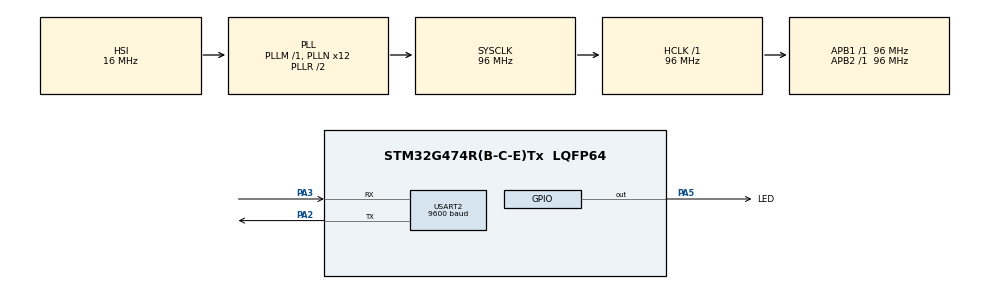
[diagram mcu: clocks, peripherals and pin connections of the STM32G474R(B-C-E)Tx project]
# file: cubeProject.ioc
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Mcu.Family=STM32G4
Mcu.Name=STM32G474R(B-C-E)Tx
Mcu.Package=LQFP64
NVIC.PriorityGroup=NVIC_PRIORITYGROUP_4
PA2.Mode=Asynchronous
PA2.Signal=USART2_TX
PA3.Mode=Asynchronous
PA3.Signal=USART2_RX
PA5.GPIO_Label=LED
PA5.Signal=GPIO_Output
PF0-OSC_IN.Mode=HSE-External-Oscillator
PF0-OSC_IN.Signal=RCC_OSC_IN
PF1-OSC_OUT.Mode=HSE-External-Oscillator
PF1-OSC_OUT.Signal=RCC_OSC_OUT
ProjectManager.HeapSize=0x200
ProjectManager.StackSize=0x400
ProjectManager.TargetToolchain=CMake
RCC.ADC12Freq_Value=96000000
RCC.ADC345Freq_Value=96000000
RCC.AHBFreq_Value=96000000
RCC.APB1Freq_Value=96000000
RCC.APB1TimFreq_Value=96000000
RCC.APB2Freq_Value=96000000
RCC.APB2TimFreq_Value=96000000
RCC.CortexFreq_Value=96000000
RCC.EXTERNAL_CLOCK_VALUE=12288000
RCC.HCLKFreq_Value=96000000
RCC.HSE_VALUE=16000000
RCC.HSI48_VALUE=48000000
RCC.HSI_VALUE=16000000
RCC.LSE_VALUE=32768
RCC.PLLN=12
RCC.PLLQ=RCC_PLLQ_DIV4
RCC.SYSCLKFreq_VALUE=96000000
RCC.SYSCLKSource=RCC_SYSCLKSOURCE_PLLCLK
RCC.USBFreq_Value=48000000
RCC.VCOOutputFreq_Value=192000000
USART2.BaudRate=9600
USART2.VirtualMode-Asynchronous=VM_ASYNC
VP_RNG_VS_RNG.Mode=RNG_Activate
VP_SYS_VS_DBSignals.Mode=DisableDeadBatterySignals
board=custom

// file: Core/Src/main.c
/* USER CODE BEGIN Header */
/**
  ******************************************************************************
  * @file           : main.c
  * @brief          : Main program body
  ******************************************************************************
  * @attention
  *
  * Copyright (c) 2026 STMicroelectronics.
  * All rights reserved.
  *
  * This software is licensed under terms that can be found in the LICENSE file
  * in the root directory of this software component.
  * If no LICENSE file comes with this software, it is provided AS-IS.
  *
  ******************************************************************************
  */
/* USER CODE END Header */
#include "main.h"
#include "rng.h"
#include "usart.h"
#include "gpio.h"

/* USER CODE BEGIN Includes */
#include "stdio.h"
#include <trng.h>
/* USER CODE END Includes */

void SystemClock_Config(void);

/* USER CODE BEGIN 0 */
int _write(int fd, char* ptr, int len){
  HAL_StatusTypeDef halStatus;
  if(fd==1 || fd==2){
    halStatus = HAL_UART_Transmit(&huart2, (uint8_t *)ptr, len, 1000);
    if(halStatus == HAL_OK){
      return len;
    }
  }
  return -1;
}

/* USER CODE END 0 */

int main(void)
{

  /* MCU Configuration--------------------------------------------------------*/

  /* Reset of all peripherals, Initializes the Flash interface and the Systick. */
  HAL_Init();

  /* Configure the system clock */
  SystemClock_Config();

  /* Initialize all configured peripherals */
  MX_GPIO_Init();
  MX_USART2_UART_Init();
  MX_RNG_Init();
  /* USER CODE BEGIN 2 */
  TRNG_DBG("Hola Amigo!\n");
  /* USER CODE END 2 */

  /* Infinite loop */
  /* USER CODE BEGIN WHILE */
  uint32_t now = 0, lastTick = 0;
  trng_init();
  while (1)
  {
    now = HAL_GetTick();
    if(now - lastTick >= 1000) {
      printf("Tick %lu, random number = %lu\n", now/1000, trng_get());
      lastTick = now;
    }
    /* USER CODE END WHILE */

  }
}

void SystemClock_Config(void)
{
  RCC_OscInitTypeDef RCC_OscInitStruct = {0};
  RCC_ClkInitTypeDef RCC_ClkInitStruct = {0};

  /** Configure the main internal regulator output voltage
  */
  HAL_PWREx_ControlVoltageScaling(PWR_REGULATOR_VOLTAGE_SCALE1);

  /** Initializes the RCC Oscillators according to the specified parameters
  * in the RCC_OscInitTypeDef structure.
  */
  RCC_OscInitStruct.OscillatorType = RCC_OSCILLATORTYPE_HSI;
  RCC_OscInitStruct.HSIState = RCC_HSI_ON;
  RCC_OscInitStruct.HSICalibrationValue = RCC_HSICALIBRATION_DEFAULT;
  RCC_OscInitStruct.PLL.PLLState = RCC_PLL_ON;
  RCC_OscInitStruct.PLL.PLLSource = RCC_PLLSOURCE_HSI;
  RCC_OscInitStruct.PLL.PLLM = RCC_PLLM_DIV1;
  RCC_OscInitStruct.PLL.PLLN = 12;
  RCC_OscInitStruct.PLL.PLLP = RCC_PLLP_DIV2;
  RCC_OscInitStruct.PLL.PLLQ = RCC_PLLQ_DIV4;
  RCC_OscInitStruct.PLL.PLLR = RCC_PLLR_DIV2;
  if (HAL_RCC_OscConfig(&RCC_OscInitStruct) != HAL_OK)
  {
    Error_Handler();
  }

  /** Initializes the CPU, AHB and APB buses clocks
  */
  RCC_ClkInitStruct.ClockType = RCC_CLOCKTYPE_HCLK|RCC_CLOCKTYPE_SYSCLK
                              |RCC_CLOCKTYPE_PCLK1|RCC_CLOCKTYPE_PCLK2;
  RCC_ClkInitStruct.SYSCLKSource = RCC_SYSCLKSOURCE_PLLCLK;
  RCC_ClkInitStruct.AHBCLKDivider = RCC_SYSCLK_DIV1;
  RCC_ClkInitStruct.APB1CLKDivider = RCC_HCLK_DIV1;
  RCC_ClkInitStruct.APB2CLKDivider = RCC_HCLK_DIV1;

  if (HAL_RCC_ClockConfig(&RCC_ClkInitStruct, FLASH_LATENCY_3) != HAL_OK)
  {
    Error_Handler();
  }
}

void Error_Handler(void)
{
  __disable_irq();
  while (1)
  {
  }
}
